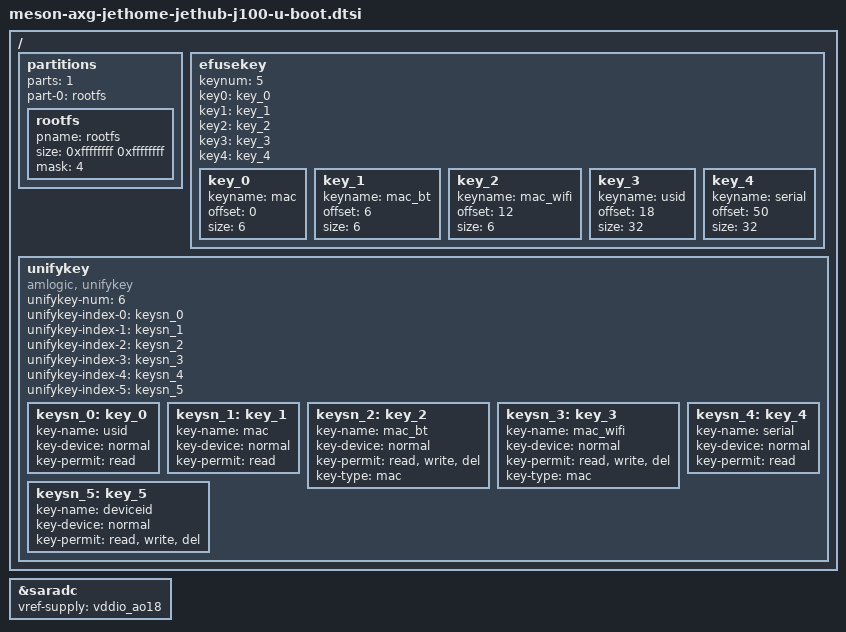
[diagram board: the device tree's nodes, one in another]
// SPDX-License-Identifier: (GPL-2.0+ OR MIT)
/*
 * Copyright (c) 2022 Vyacheslav Bocharov <adeep@lexina.in>
 * Author: Vyacheslav Bocharov <adeep@lexina.in>
 */

/ {
	partitions: partitions {
		parts = <1>;
		part-0 = <&rootfs>;
		rootfs: rootfs {
			pname = "rootfs";
			size = <0xffffffff 0xffffffff>;
			mask = <4>;
		};
	};

	efusekey: efusekey {
		keynum = <5>;
		key0 = <&key_0>;
		key1 = <&key_1>;
		key2 = <&key_2>;
		key3 = <&key_3>;
		key4 = <&key_4>;

		key_0: key_0 {
			keyname = "mac";
			offset = <0>;
			size = <6>;
		};
		key_1: key_1 {
			keyname = "mac_bt";
			offset = <6>;
			size = <6>;
		};
		key_2: key_2 {
			keyname = "mac_wifi";
			offset = <12>;
			size = <6>;
		};
		key_3: key_3 {
			keyname = "usid";
			offset = <18>;
			size = <32>;
		};
		key_4: key_4 {
			keyname = "serial";
			offset = <50>;
			size = <32>;
		};
	}; //End efusekey

	unifykey {
		compatible = "amlogic, unifykey";
		status = "ok";
		unifykey-num = <6>;
		unifykey-index-0 = <&keysn_0>;
		unifykey-index-1 = <&keysn_1>;
		unifykey-index-2 = <&keysn_2>;
		unifykey-index-3 = <&keysn_3>;
		unifykey-index-4 = <&keysn_4>;
		unifykey-index-5 = <&keysn_5>;

		keysn_0: key_0 {
			key-name = "usid";
			key-device = "normal";
			key-permit = "read";
		};
		keysn_1: key_1 {
			key-name = "mac";
			key-device = "normal";
			key-permit = "read";
		};
		keysn_2: key_2 {
			key-name = "mac_bt";
			key-device = "normal";
			key-permit = "read","write","del";
			key-type  = "mac";
		};
		keysn_3: key_3 {
			key-name = "mac_wifi";
			key-device = "normal";
			key-permit = "read","write","del";
			key-type = "mac";
		};
		keysn_4: key_4 {
			key-name = "serial";
			key-device = "normal";
			key-permit = "read";
		};
		keysn_5:key_5 {
			key-name = "deviceid";
			key-device = "normal";
			key-permit = "read","write","del";
		};
	}; //End unifykey
};

&saradc {
	status = "okay";
	vref-supply = <&vddio_ao18>;
};
